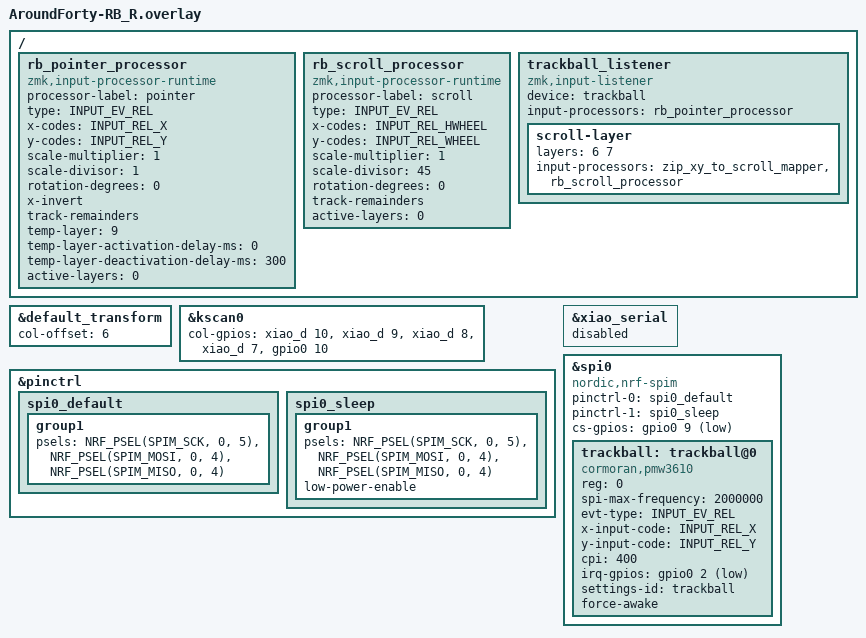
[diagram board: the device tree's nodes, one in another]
#include "AroundForty-RB.dtsi"
#include <dt-bindings/zmk/pointing.h>
#include <dt-bindings/zmk/input_transform.h>
#include <input/processors.dtsi>
#include <input/processors/runtime-input-processor.dtsi>
#include <zephyr/dt-bindings/input/input-event-codes.h>

&default_transform {
    col-offset = <6>;
};

&kscan0 {
    col-gpios
        = <&xiao_d 10 GPIO_ACTIVE_HIGH>
        , <&xiao_d  9 GPIO_ACTIVE_HIGH>
        , <&xiao_d  8 GPIO_ACTIVE_HIGH>
        , <&xiao_d  7 GPIO_ACTIVE_HIGH>
        , <&gpio0  10 GPIO_ACTIVE_HIGH>
        ;
};


/ {
    /* 現行ファームウェアの X 反転・等倍設定を初期値として引き継ぐ。 */
    rb_pointer_processor: rb_pointer_processor {
        compatible = "zmk,input-processor-runtime";
        processor-label = "pointer";
        type = <INPUT_EV_REL>;
        x-codes = <INPUT_REL_X>;
        y-codes = <INPUT_REL_Y>;
        scale-multiplier = <1>;
        scale-divisor = <1>;
        rotation-degrees = <0>;
        x-invert;
        track-remainders;

        /* Studio から有効化した場合は AML (layer 9) を使う。 */
        temp-layer = <9>;
        temp-layer-activation-delay-ms = <0>;
        temp-layer-deactivation-delay-ms = <300>;
        active-layers = <0>;
        #input-processor-cells = <0>;
    };

    /* 現行の 1/45 スクロール倍率を初期値として引き継ぐ。 */
    rb_scroll_processor: rb_scroll_processor {
        compatible = "zmk,input-processor-runtime";
        processor-label = "scroll";
        type = <INPUT_EV_REL>;
        x-codes = <INPUT_REL_HWHEEL>;
        y-codes = <INPUT_REL_WHEEL>;
        scale-multiplier = <1>;
        scale-divisor = <45>;
        rotation-degrees = <0>;
        track-remainders;
        active-layers = <0>;
        #input-processor-cells = <0>;
    };

    trackball_listener: trackball_listener {
        compatible = "zmk,input-listener";
        device = <&trackball>;
        input-processors = <&rb_pointer_processor>;

        scroll-layer {
            layers = <6 7>;
            input-processors = <&zip_xy_to_scroll_mapper>,
                               <&rb_scroll_processor>;
        };
    };
};

&pinctrl {
    spi0_default: spi0_default {
        group1 {
            psels = <NRF_PSEL(SPIM_SCK,  0, 5)>,
                    <NRF_PSEL(SPIM_MOSI, 0, 4)>,
                    <NRF_PSEL(SPIM_MISO, 0, 4)>;
        };
    };

    spi0_sleep: spi0_sleep {
        group1 {
            psels = <NRF_PSEL(SPIM_SCK,  0, 5)>,
                    <NRF_PSEL(SPIM_MOSI, 0, 4)>,
                    <NRF_PSEL(SPIM_MISO, 0, 4)>;
            low-power-enable;
        };
    };
};

&xiao_serial { status = "disabled"; };

&spi0 {
    status = "okay";
    compatible = "nordic,nrf-spim";
    pinctrl-0 = <&spi0_default>;
    pinctrl-1 = <&spi0_sleep>;
    pinctrl-names = "default", "sleep";
    cs-gpios = <&gpio0 9 GPIO_ACTIVE_LOW>;

    trackball: trackball@0 {
        status = "okay";
        compatible = "cormoran,pmw3610";
        reg = <0>;
        spi-max-frequency = <2000000>;
        evt-type = <INPUT_EV_REL>;
        x-input-code = <INPUT_REL_X>;
        y-input-code = <INPUT_REL_Y>;
        cpi = <400>;
        irq-gpios = <&gpio0 2 (GPIO_ACTIVE_LOW | GPIO_PULL_UP)>;
        settings-id = "trackball";
        force-awake;
    };
};
